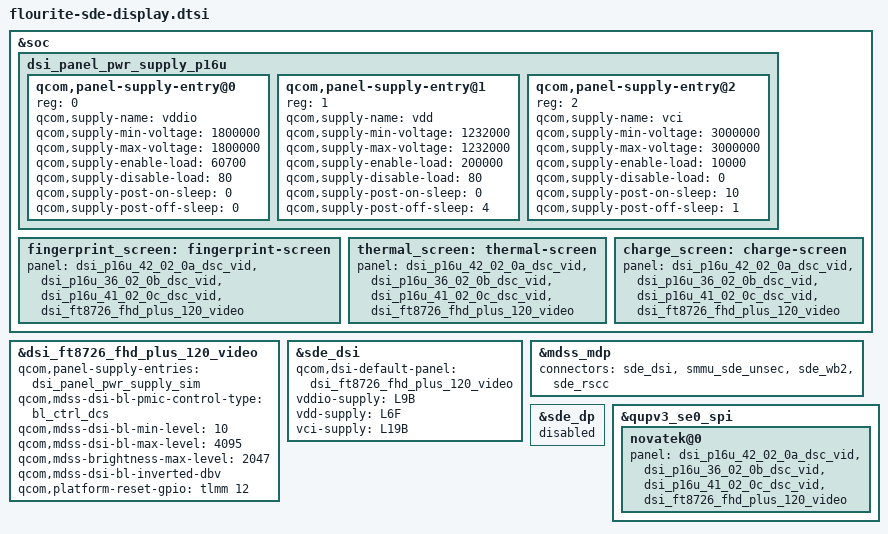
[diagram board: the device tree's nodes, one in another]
#include "volcano-sde-display.dtsi"
#include "dsi-panel-p16u-42-02-0a-dsc-vid.dtsi"
#include "dsi-panel-p16u-36-02-0b-dsc-vid.dtsi"
#include "dsi-panel-p16u-41-02-0c-dsc-vid.dtsi"

&soc {
		dsi_panel_pwr_supply_p16u: dsi_panel_pwr_supply_p16u {
		#address-cells = <1>;
		#size-cells = <0>;
		qcom,panel-supply-entry@0 {
			reg = <0>;
			qcom,supply-name = "vddio";
			qcom,supply-min-voltage = <1800000>;
			qcom,supply-max-voltage = <1800000>;
			qcom,supply-enable-load = <60700>;
			qcom,supply-disable-load = <80>;
			qcom,supply-post-on-sleep = <0>;
			qcom,supply-post-off-sleep = <0>;
		};
		qcom,panel-supply-entry@1 {
			reg = <1>;
			qcom,supply-name = "vdd";
			qcom,supply-min-voltage = <1232000>;
			qcom,supply-max-voltage = <1232000>;
			qcom,supply-enable-load = <200000>;
			qcom,supply-disable-load = <80>;
			qcom,supply-post-on-sleep = <0>;
			qcom,supply-post-off-sleep = <4>;
		};
		qcom,panel-supply-entry@2 {
			reg = <2>;
			qcom,supply-name = "vci";
			qcom,supply-min-voltage = <3000000>;
			qcom,supply-max-voltage = <3000000>;
			qcom,supply-enable-load = <10000>;
			qcom,supply-disable-load = <0>;
			qcom,supply-post-on-sleep = <10>;
			qcom,supply-post-off-sleep = <1>;
		};
	};
};

&dsi_ft8726_fhd_plus_120_video {
	qcom,panel-supply-entries = <&dsi_panel_pwr_supply_sim>;
	qcom,mdss-dsi-bl-pmic-control-type = "bl_ctrl_dcs";
	qcom,mdss-dsi-bl-min-level = <10>;
	qcom,mdss-dsi-bl-max-level = <4095>;
	qcom,mdss-brightness-max-level = <2047>;
	qcom,mdss-dsi-bl-inverted-dbv;
	qcom,platform-reset-gpio = <&tlmm 12 0>;
};

&sde_dsi {
	qcom,dsi-default-panel = <&dsi_ft8726_fhd_plus_120_video>;
	vddio-supply = <&L9B>;
	vdd-supply = <&L6F>;
	vci-supply = <&L19B>;
};

&soc {
	fingerprint_screen: fingerprint-screen {
		panel = <&dsi_p16u_42_02_0a_dsc_vid
			&dsi_p16u_36_02_0b_dsc_vid
			&dsi_p16u_41_02_0c_dsc_vid
			&dsi_ft8726_fhd_plus_120_video>;
	};
};

&mdss_mdp {
	connectors = <&sde_dsi &smmu_sde_unsec &sde_wb2 &sde_rscc>;
};

&sde_dp {
	status = "disabled";
};

&soc {
	thermal_screen: thermal-screen {
		panel = <&dsi_p16u_42_02_0a_dsc_vid
			&dsi_p16u_36_02_0b_dsc_vid
			&dsi_p16u_41_02_0c_dsc_vid
			&dsi_ft8726_fhd_plus_120_video>;
	};
	charge_screen: charge-screen {
		panel = <&dsi_p16u_42_02_0a_dsc_vid
			&dsi_p16u_36_02_0b_dsc_vid
			&dsi_p16u_41_02_0c_dsc_vid
			&dsi_ft8726_fhd_plus_120_video>;
	};
};

&qupv3_se0_spi {
	novatek@0 {
		panel = <&dsi_p16u_42_02_0a_dsc_vid
			&dsi_p16u_36_02_0b_dsc_vid
			&dsi_p16u_41_02_0c_dsc_vid
			&dsi_ft8726_fhd_plus_120_video>;
	};
};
